# psoc4hvpaspm10 register map
Vendor: Infineon Technologies; Series: PSOC4HVPASPM10; File version: 1.0
CPU: CM0PLUS r0p1, little endian, MPU, no FPU, VTOR, 2 interrupt priority bits, 32 interrupts
Registers are 32-bit, read-write, reset 0x0 unless marked. A register's access mark holds for its fields unless they carry their own. Offsets are from the block's base; lines under a group give offsets from that group; [hi:lo] are bit positions; {n}, {i} and the like mark numbered series; 'fields as' and 'values as' point back to an identical list; <NAME> marks a mode.

## Memory map
0x40010000 PERI size 0x10000 — Peripheral Interconnect
0x40020000 HSIOM size 0x4000 — High Speed IO Matrix (HSIOM)
0x40030000 SRSSHV size 0x10000 — System Resources High Voltage Subsystem
0x40040000 GPIO size 0x4000 — GPIO port control/configuration
0x40060000 HVSS size 0x10000 — High Voltage Subsystem
0x400C0000 CRYPTO size 0x10000 — Cryptography component
0x400F0000 EXCO size 0x10000 — ECO+PLL as SRSSLT clk_eco external source
0x40100000 CPUSS size 0x1000 — CPU Subsystem
0x40101000 DMAC size 0x1000 — DataWire/DMA Controller
0x40110000 SPCIF size 0x10000 — Flash Control Interface
0x40120000 SPCIF1 size 0x10000 — Flash Control Interface
0x40130000 FAULT size 0x10000 — Fault structures
0x40200000 TCPWM size 0x10000 — Timer/Counter/PWM
0x40220000 CANFD0 size 0x20000 — CAN Controller
0x40240000 SCB0 size 0x10000 — Serial Communications Block (SPI/UART/I2C)
0x40250000 SCB1 size 0x10000
0x402D0000 LIN0 size 0x10000 — LIN
0x402E0000 ISOUART size 0x10000 — iso-UART Block
0x40300000 PACSS size 0x100000 — Programmable Analog Channel Sub-System

## Interrupts
0 srss_interrupt_srss (CPUSS) — SRSS interrupts
1 srss_wdt_irq (CPUSS) — WDT Interrupt
2 ioss_interrupt_gpio (CPUSS) — GPIO consolidated interrupt
3 ioss_interrupts_gpio_0 (CPUSS) — GPIO P0
4 ioss_interrupts_gpio_2 (CPUSS) — GPIO P2
5 ioss_interrupts_gpio_3 (CPUSS) — GPIO P3
6 hvss_interrupt_hvss (CPUSS) — HVSS interface interrupt
7 scb_0_interrupt (CPUSS)
8 scb_1_interrupt (CPUSS)
9 isouart_interrupt (CPUSS)
10 cpuss_interrupt_dma (CPUSS) — DMA Interrupt
11 cpuss_interrupt_spcif (CPUSS) — SPCIF interrupt
12 cpuss_interrupt_spcif1 (CPUSS) — SPCIF interrupt, controller 1
13 cpuss_interrupt_fault_0 (CPUSS) — Fault structure 0 interrupt
14 cpuss_interrupt_fault_1 (CPUSS) — Fault structure 1 interrupt
15 tcpwm_interrupts_0 (CPUSS) — TCPWM #0, Counter #0
16 tcpwm_interrupts_1 (CPUSS) — TCPWM #0, Counter #1
17 tcpwm_interrupts_2 (CPUSS) — TCPWM #0, Counter #2
18 tcpwm_interrupts_3 (CPUSS) — TCPWM #0, Counter #3
19 tcpwm_interrupts_4 (CPUSS) — TCPWM #0, Counter #4
20 pacss_interrupt (CPUSS) — PACSS consolidated interrupt
21 pacss_interrupts_dch_0 (CPUSS) — PACSS digital channel #0
22 pacss_interrupts_dch_1 (CPUSS) — PACSS digital channel #1
23 pacss_interrupts_dch_2 (CPUSS) — PACSS digital channel #2
24 pacss_interrupts_dch_3 (CPUSS) — PACSS digital channel #3
25 pacss_interrupt_mmio (CPUSS) — PACSS mmio
26 crypto_interrupt (CPUSS)
27 exco_interrupt (CPUSS)
28 canfd_interrupts0_0 (CPUSS) — Canfd Int 0 for channel 0
29 canfd_interrupts1_0 (CPUSS) — Canfd Int 1 for channel 0
30 lin_interrupts_0 (CPUSS) — LIN interrupt, channel #0
31 lin_interrupts_1 (CPUSS) — LIN interrupt, channel #1

## HSIOM — High Speed IO Matrix (HSIOM)
Base 0x40020000
{0x0+0x100*i} PRT[{i}] (i=0..4) group — HSIOM port registers
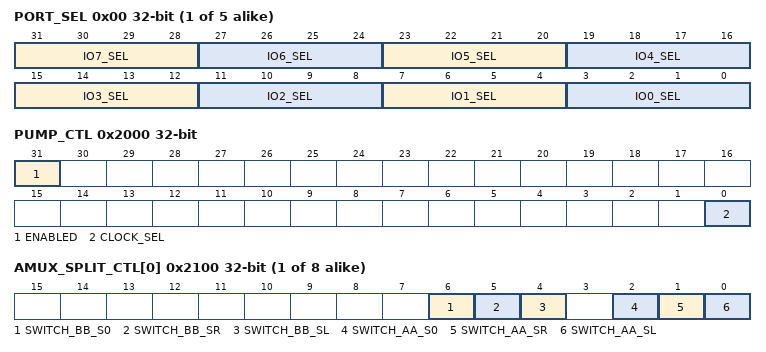
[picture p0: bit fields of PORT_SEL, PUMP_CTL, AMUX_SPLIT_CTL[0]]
  0x00 PORT_SEL — Port selection register
    [4n+3:4n] IO{n}_SEL (n=1..7)
    [3:0] IO0_SEL
      0=GPIO (SW controlled GPIO.); 1=GPIO_DSI (SW controlled 'out', DSI controlled 'oe_n'.); 2=DSI_DSI (DSI controlled 'out' and 'oe_n'.); 3=DSI_GPIO (DSI controlled 'out', SW controlled 'oe_n'.); 4=CSD_SENSE (CSD sense connection (analog mode)); 5=CSD_SHIELD (CSD shield connection (analog mode)); 6=AMUXA (AMUXBUS A connection.); 7=AMUXB (AMUXBUS B connection. This mode is also used for CSD GPIO charging. When CSD GPIO charging is enabled in CSD_CONTROL, 'oe_n' is connected to '!csd_charge' signal (and IO pad is also still connected to AMUXBUS B).); {v}=ACT_{v-8} (Chip specific Active source {v-8} connection.) (v=8..11); 12=LCD_COM (LCD common connection. This mode provides DeepSleep functionality (provided that the LCD block exists, is enabled, and is properly configured).); 13=LCD_SEG (LCD segment connection. This mode provides DeepSleep functionality (provided that the LCD block is enabled and properly configured).); 14=DS_2 (Chip specific DeepSleep source 2 connection.); 15=DS_3 (Chip specific DeepSleep source 3 connection.)
0x2000 PUMP_CTL — Pump control
  [31] ENABLED — Pump enabled: '0': Disabled. '1': Enabled.
  [0] CLOCK_SEL — Clock select: '0': External clock. '1': Internal clock (deprecated).
{0x2100+4i} AMUX_SPLIT_CTL[{i}] (i=0..7) — AMUX splitter cell control
  [6] SWITCH_BB_S0 — T-switch control for AMUXBUSB vssa/ground switch.
  [5] SWITCH_BB_SR — T-switch control for Right AMUXBUSB switch.
  [4] SWITCH_BB_SL — T-switch control for Left AMUXBUSB switch.
  [2] SWITCH_AA_S0 — T-switch control for AMUXBUSA vssa/ground switch: '0': switch open. '1': switch closed.
  [1] SWITCH_AA_SR — T-switch control for Right AMUXBUSA switch: '0': switch open. '1': switch closed.
  [0] SWITCH_AA_SL — T-switch control for Left AMUXBUSA switch: '0': switch open. '1': switch closed.

## Licence text in the file
(c) 2016-2026, Infineon Technologies AG or an affiliate of. Infineon Technologies AG. SPDX-License-Identifier: Apache-2.0 . Licensed under the Apache License, Version 2.0 (the "License"); you may not use this file except in compliance with the License. You may obtain a copy of the License at http://www.apache.org/licenses/LICENSE-2.0 . Unless required by applicable law or agreed to in writing, software distributed under the License is distributed on an "AS IS" BASIS, WITHOUT WARRANTIES OR CONDITIONS OF ANY KIND, either express or implied. See the License for the specific language governing permissions and limitations under the License.
